# N575F145_v1 register map
File version: 1.0
Registers are 32-bit, read-write, reset 0x0 unless marked. A register's access mark holds for its fields unless they carry their own. Offsets are from the block's base; [hi:lo] are bit positions.

## ANA — ANA Register Map
Base 0x40080000
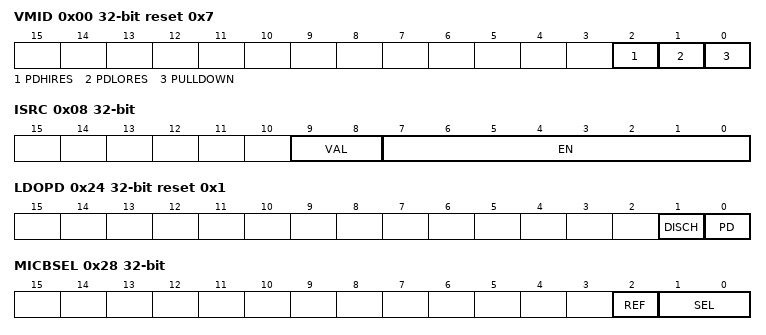
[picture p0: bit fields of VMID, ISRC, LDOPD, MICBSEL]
0x00 VMID reset 0x7 — VMID Reference Control Register
  [2] PDHIRES — Power Down High (360kΩ) Resistance Reference
    0=Connect the High Resistance reference to VMID. Use this setting for minimum power consumption; 1=The High Resistance reference is disconnected from VMID. Default power down and reset condition
  [1] PDLORES — Power Down Low (4.8kΩ) Resistance Reference
    0=Connect the Low Resistance reference to VMID. Use this setting for fast power up of VMID. Can be turned off after 50ms to save power; 1=The Low Resistance reference is disconnected from VMID. Default power down and reset condition
  [0] PULLDOWN — VMID Pulldown
    0=Release VMID pin for reference operation; 1=Pull VMID pin to ground. Default power down and reset condition
0x08 ISRC — Current Source Control Register
  [9:8] VAL — Current Source Value. Select master current for source generation
    0=0.5 uA; 1=1 uA; 2=2.5 uA; 3=5 uA
  [7:0] EN — Enable Current Source to GPIOB[x]. Individually enable current source to GPIOB pins. Each GPIOB pin has a separate current source.
    0=Disable; 1=Enable current source to pin GPIOB[x]
0x20 LDOSET — LDO Voltage Select Register
  [1:0] LDOSET — Select LDO Output Voltage. Note that maximum I/O pad operation speed only specified for voltage >2.4V.
    0=3.0V; 1=1.8V; 2=2.4V; 3=3.3V
0x24 LDOPD reset 0x1 — LDO Power Down Register
  [1] DISCH — Discharge
    0=No load on VD33; 1=Switch discharge resistor to VD33
  [0] PD — Power Down LDO. When powered down no current delivered to VD33.
    0=Enable LDO; 1=Power Down
0x28 MICBSEL — Microphone Bias Select Register
  [2] REF — Select Reference Source For MICBIAS Generator. VMID provides superior noise performance for MICBIAS generation and should be used unless fixed voltage is absolutely necessary, then noise performance can be sacrificed and bandgap voltage used as reference.
    0=VMID = VCCA/2 is reference source; 1=VBG (bandgap voltage reference) is reference source
  [1:0] SEL — Select Microphone Bias Voltage. MICBMODE = 0. 0: 90% VCCA. 1: 65% VCCA. 2: 75% VCCA. 3: 50% VCCA. MICBMODE = 1. 0: 2.4V. 1: 1.7V. 2: 2.0V. 3: 1.3V
0x2C MICBEN — Microphone Bias Enable Register
  [0] MICBEN — Enable Microphone Bias Generator
    0=Powered Down; 1=Enabled
0x38 VSET — Logic Power Control Register
0x3C TMPOWER — Power Test Mode Register
0x40 TMANALOG — Analog Test Mode Register
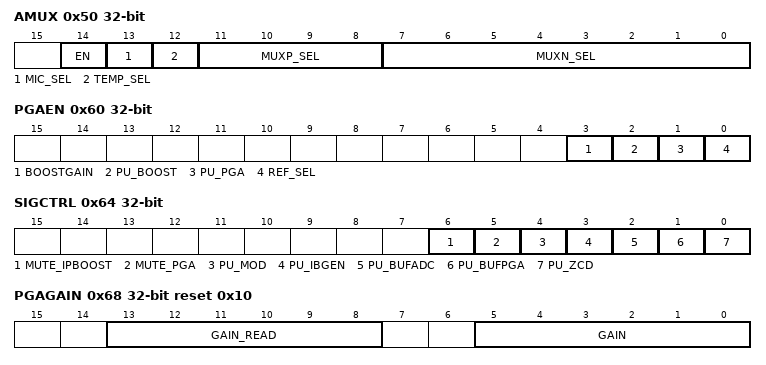
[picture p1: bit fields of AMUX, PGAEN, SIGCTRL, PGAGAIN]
0x50 AMUX — Analog Multiplexer Control Register
  [14] EN — Enable The Analog Multiplexer
    0=All channels disabled; 1=Selection determined by register setting
  [13] MIC_SEL — Select MICP/MICN To PGA Inputs
  [12] TEMP_SEL — Select PTAT Current. I_PTAT, to PGA_INN, negative input to PGA, for temperature measurement.
  [11:8] MUXP_SEL — Selects Connection Of GPIOB[7,5,3,1] To PGA_INP, Positive Input Of PGA. 1000b: GPIOB[7] connected to PGA_INP. 0100b: GPIOB[5] connected to PGA_INP. 0010b: GPIOB[3] connected to PGA_INP. 0001b: GPIOB[1] connected to PGA_INP
  [7:0] MUXN_SEL — Selects Connection Of GPIOB[7:0] To PGA_INN, Negative Input Of PGA. If MUXN_SEL[n] = 1 then GPIOB[n] is connected to PGA_INN.
0x60 PGAEN — PGA Enable Register
  [3] BOOSTGAIN — Boost Stage Gain Setting
    0=Gain = 0dB; 1=Gain = 26dB
  [2] PU_BOOST — Power Up Control For Boost Stage Amplifier. This amplifier must be powered up for signal path operation.
    0=Power Down; 1=Power up
  [1] PU_PGA — Power Up Control For PGA Amplifier. This amplifier must be powered up for signal path operation.
    0=Power Down; 1=Power up
  [0] REF_SEL — Select Reference For Analog Path. Signal path is normally referenced to VMID (VCCA/2). To use an absolute reference this can be set to VBG = 1.2V.
    0=Select VMID voltage as analog ground reference; 1=Select Bandgap voltage as analog ground reference
0x64 SIGCTRL — Signal Path Control Register
  [6] MUTE_IPBOOST — Boost Stage Mute Control
    0=Normal; 1=Signal Muted
  [5] MUTE_PGA — PGA Mute Control
    0=Normal; 1=Signal Muted
  [4] PU_MOD — Power Up ADC ΣΔ Modulator. This block must be powered up for ADC operation.
    0=Power down; 1=Power up
  [3] PU_IBGEN — Power Up Control For Current Bias Generation. This block must be powered up for signal path operation.
    0=Power down; 1=Power up
  [2] PU_BUFADC — Power Up Control For ADC Reference Buffer. This block must be powered up for signal path operation.
    0=Power down; 1=Power up
  [1] PU_BUFPGA — Power Up Control For PGA Reference Buffer. This block must be powered up for signal path operation.
    0=Power down; 1=Power up
  [0] PU_ZCD — Power Up And Enable Control For Zero Cross Detect Comparator. When enabled PGA gain settings will only be updated when ADC input signal crosses zero signal threshold. To operate ZCD the ALC peripheral clock (SYSCLK.BIQALC_EN) must also be enabled and BIQ->BIQ_CTRL.RSTn = 1 to allow ZCD clocks to be generated.
    0=Power down; 1=Power up and enable zero cross detection
0x68 PGAGAIN reset 0x10 — PGA Gain Select Register
  [13:8] GAIN_READ — Current PGA Gain. Read Only. May be different from GAIN register when AGC is enabled and is controlling the PGA gain.
  [5:0] GAIN — Select The PGA Gain Setting. From -12dB to 35.25dB in 0.75dB step size. 0x00 is lowest gain setting at -12dB and 0x3F is largest gain at 35.25dB.
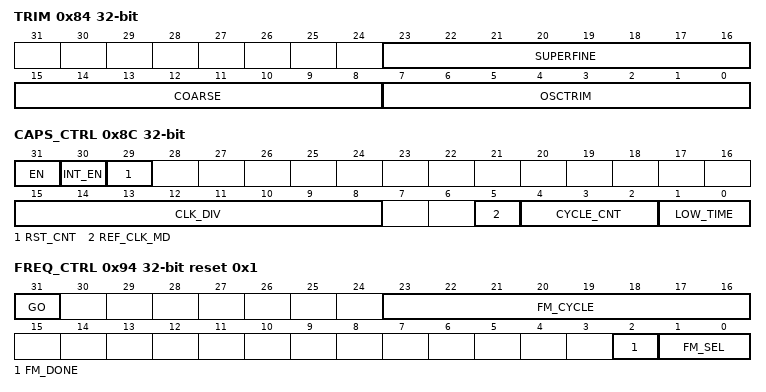
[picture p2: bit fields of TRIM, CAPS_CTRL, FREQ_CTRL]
0x84 TRIM (reset mask 0xFFFF0000) — Oscillator Trim Register
  [23:16] SUPERFINE — Superfine. The SUPERFINE trim setting is an 8bit signed integer. It adjusts the master oscillator by dithering the FINE trim setting between the current setting and one setting above (values 1,127) or below (values -1, -128) the current trim setting. Each step effectively moves the frequency 1/128th of the full FINE trim step size.
  [15:8] COARSE — COARSE. Current COARSE range setting of the oscillator. Read Only
  [7:0] OSCTRIM — Oscillator Trim. Reads current oscillator trim setting. Read Only.
0x8C CAPS_CTRL — Capacitive Touch Sensing Control Register
  [31] EN — Enable
    0=Disable/Reset block; 1=Enable Block
  [30] INT_EN — Interrupt Enable
    0=Disable/Reset CAPS_IRQ interrupt; 1=Enable CAPS_IRQ interrupt
  [29] RST_CNT — Reset Count. 0: Release/Activate CAP_CNT. 1: Set high to reset CAP_CNT.
  [15:8] CLK_DIV — Reference Clock Divider. Circuit can be used to generate a reference clock output of SDCLK/2/(CLK_DIV+1) instead of a Capacitive Touch Sensing reset signal.
  [5] REF_CLK_MD — Reference Clock Mode
    0=Capacitive Touch Sensing Mode; 1=Circuit is in Reference clock generation mode
  [4:2] CYCLE_CNT — Number of Relaxation Cycles. Peripheral performs 2^(CYCLE_CNT) relaxation cycles before generating interrupt.
  [1:0] LOW_TIME — Output Low Time. Number of PCLK cycles to discharge external capacitor.
    0=1cycle; 1=2cycles; 2=8cycles; 3=16cycles
0x90 CAPS_CNT ro — Capacitive Touch Sensing Count Register
  [23:0] CAPS_CNT — Counter Read Back Value Of Capacitive Touch Sensing Block
0x94 FREQ_CTRL reset 0x1 — Frequency Measurement Control Register
  [31] GO
    0=Disable/Reset block; 1=Start Frequency Measurement
  [23:16] FM_CYCLE — Frequency Measurement Cycles. Number of reference clock periods plus one to measure target clock (PCLK). For example if reference clock is OSC32K (T is 30.5175us), set FM_CYCLE to 7, then measurement period would be 30.5175*(7+1), 244.1us.
  [2] FM_DONE — Measurement Done
    0=Measurement Ongoing; 1=Measurement Complete
  [1:0] FM_SEL — Reference Clock Source. 00b: OSC16K, 01b: OSC32K (default), 1xb: I2S_WS - can be GPIOA[4,8,12] according to GPA_ALT register, configure I2S in SLAVE mode to enable.
0x98 FREQ_CNT ro — Frequency Measurement Count Register
  [15:0] FREQ_CNT — Frequency Measurement Count. When FM_DONE = 1 and G0 = 1, this is number of PCLK periods counted for frequency measurement. The frequency will be PCLK = FREQ_CNT * Fref /(FM_CYCLE+1) Hz. Maximum resolution of measurement is Fref /(FM_CYCLE+1)*2 Hz
